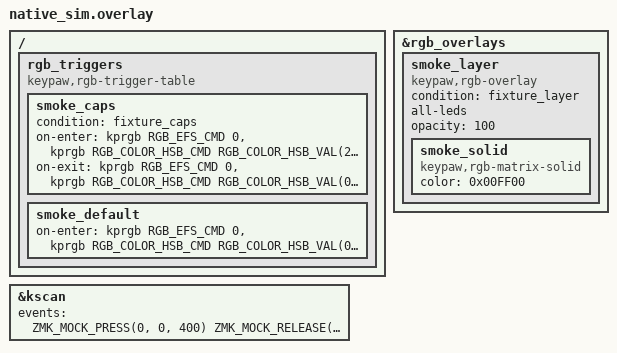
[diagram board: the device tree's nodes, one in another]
/*
 * Copyright (c) 2026 The ZMK Contributors
 *
 * SPDX-License-Identifier: MIT
 *
 * Smoke-test fixture: reuses the preview devicetree and overrides only what the
 * scenario needs -- a visible layer overlay and the scripted key events. Run
 * with tests/sim/run-smoke.sh; the assertions live in check_capture.py.
 */

#include "../config/native_sim.overlay"

#include <dt-bindings/keypaw/rgb_matrix.h>

/* The trigger is the sole pixel path for Caps Lock: fixture_or is inert. */
/ {
    rgb_triggers: rgb_triggers {
        compatible = "keypaw,rgb-trigger-table";

        smoke_caps: smoke_caps {
            condition = <&fixture_caps>;
            on-enter = <&kprgb RGB_EFS_CMD 0>,
                       <&kprgb RGB_COLOR_HSB_CMD RGB_COLOR_HSB_VAL(240, 100, 100)>;
            on-exit = <&kprgb RGB_EFS_CMD 0>,
                      <&kprgb RGB_COLOR_HSB_CMD RGB_COLOR_HSB_VAL(0, 100, 100)>;
        };

        smoke_default: smoke_default {
            on-enter = <&kprgb RGB_EFS_CMD 0>,
                       <&kprgb RGB_COLOR_HSB_CMD RGB_COLOR_HSB_VAL(0, 100, 100)>;
        };
    };
};

/* Drop the preview typing cadence; the scenario below scripts its own. */
&kscan {
    /delete-property/ events;
};

/* The preview fixture_overlay names no targets, so it paints nothing. This one
 * is `all-leds` at full opacity, so holding layer 1 covers every LED. */
&rgb_overlays {
    smoke_layer: smoke_layer {
        compatible = "keypaw,rgb-overlay";
        condition = <&fixture_layer>;
        all-leds;
        opacity = <100>;

        smoke_solid: smoke_solid {
            compatible = "keypaw,rgb-matrix-solid";
            #binding-cells = <0>;
            color = <0x00FF00>;
        };
    };
};

/* Scenario, ms since the previous event (positions from the identity transform
 * are row * 12 + col):
 *    400  RC(0,0)=0  RGB_OFF  -> strip blanks
 *   1000  RC(1,0)=12 RGB_ON   -> solid red again
 *   1500  RC(1,1)=13 reactive -> idles at its background floor
 *   2600  RC(2,0)=24 key press-> reactive flash on that key's LED
 *   3400  RC(3,0)=36 &mo 1    -> layer overlay covers green, released at 3900
 *
 * The run also injects Caps Lock from the host (run-smoke.sh --caps-on/--caps-off,
 * 4200/5500 ms): the trigger table recolours solid blue, then red again. Caps
 * Lock is not a key event, so this path does not appear in `events` below. */
&kscan {
    events = <
        ZMK_MOCK_PRESS(0, 0, 400) ZMK_MOCK_RELEASE(0, 0, 60)
        ZMK_MOCK_PRESS(1, 0, 540) ZMK_MOCK_RELEASE(1, 0, 60)
        ZMK_MOCK_PRESS(1, 1, 440) ZMK_MOCK_RELEASE(1, 1, 60)
        ZMK_MOCK_PRESS(2, 0, 1040) ZMK_MOCK_RELEASE(2, 0, 60)
        ZMK_MOCK_PRESS(3, 0, 740) ZMK_MOCK_RELEASE(3, 0, 500)
    >;
};
